# USB_Operation_1 register map
Vendor: Texas Instruments
Peripheral module from a debugger description file (folder msp430).
Registers are 8-bit, access not given, no defined reset value unless marked. A register's access mark holds for its fields unless they carry their own. Offsets are as the file gives them; lines under a group give offsets from that group; [hi:lo] are bit positions; {n}, {i} and the like mark numbered series; 'fields as' and 'values as' point back to an identical list; <NAME> marks a mode.

## USB_Operation
0x1C00 USBSTABUFF — Start of buffer space
0x236F USBTOPBUFF — Top of buffer space
0x2370 USBOEP0BUF — Output endpoint_0 buffer
0x2378 USBIEP0BUF — Input endpoint_0 buffer
0x2380 USBSUBLK — Setup Packet Block
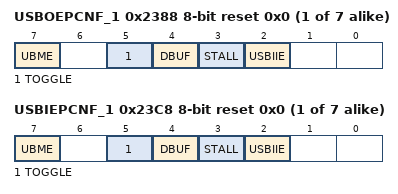
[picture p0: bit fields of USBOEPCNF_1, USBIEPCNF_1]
{0x2380+8i} USBOEPCNF_{i} rw reset 0x0 (i=1..7) — Output Endpoint_{i}: Configuration
  [7] UBME — USB - UBM In-Endpoint Enable
  [5] TOGGLE — USB - Toggle Bit
  [4] DBUF — USB - Double Buffer Enable
  [3] STALL — USB - Stall Condition
  [2] USBIIE — USB - Transaction Interrupt indication enable
{0x2381+8i} USBOEPBBAX_{i} (i=1..7) — Output Endpoint_{i}: X-buffer base addr.
{0x2382+8i} USBOEPBCTX_{i} (i=1..7) — Output Endpoint_{i}: X-byte count
{0x2385+8i} USBOEPBBAY_{i} (i=1..7) — Output Endpoint_{i}: Y-buffer base addr.
{0x2386+8i} USBOEPBCTY_{i} (i=1..7) — Output Endpoint_{i}: Y-byte count
{0x2387+8i} USBOEPSIZXY_{i} (i=1..7) — Output Endpoint_{i}: X/Y-buffer size
{0x23C0+8i} USBIEPCNF_{i} rw reset 0x0 (i=1..7) — Input Endpoint_{i}: Configuration
  fields as USBOEPCNF_1
{0x23C1+8i} USBIEPBBAX_{i} (i=1..7) — Input Endpoint_{i}: X-buffer base addr.
{0x23C2+8i} USBIEPBCTX_{i} (i=1..7) — Input Endpoint_{i}: X-byte count
{0x23C5+8i} USBIEPBBAY_{i} (i=1..7) — Input Endpoint_{i}: Y-buffer base addr.
{0x23C6+8i} USBIEPBCTY_{i} (i=1..7) — Input Endpoint_{i}: Y-byte count
{0x23C7+8i} USBIEPSIZXY_{i} (i=1..7) — Input Endpoint_{i}: X/Y-buffer size
